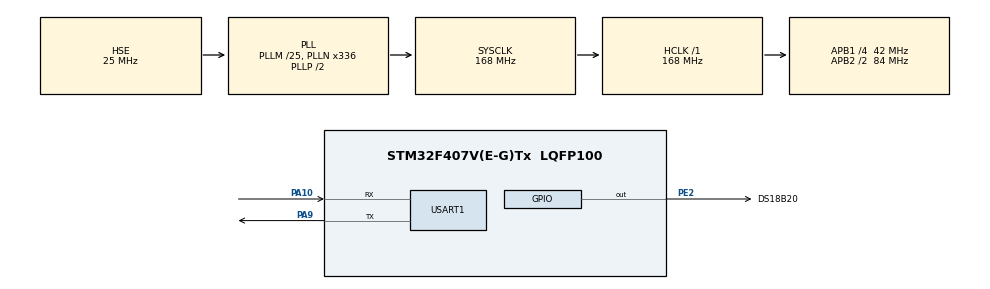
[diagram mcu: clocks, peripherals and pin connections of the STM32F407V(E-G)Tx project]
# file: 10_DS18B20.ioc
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Mcu.Family=STM32F4
Mcu.Name=STM32F407V(E-G)Tx
Mcu.Package=LQFP100
NVIC.PriorityGroup=NVIC_PRIORITYGROUP_4
PA10.GPIO_Speed=GPIO_SPEED_FREQ_HIGH
PA10.Mode=Asynchronous
PA10.Signal=USART1_RX
PA13.Mode=Serial_Wire
PA13.Signal=SYS_JTMS-SWDIO
PA14.Mode=Serial_Wire
PA14.Signal=SYS_JTCK-SWCLK
PA9.GPIO_Speed=GPIO_SPEED_FREQ_HIGH
PA9.Mode=Asynchronous
PA9.Signal=USART1_TX
PE2.GPIO_Label=DS18B20
PE2.Signal=GPIO_Output
PH0-OSC_IN.Mode=HSE-External-Oscillator
PH0-OSC_IN.Signal=RCC_OSC_IN
PH1-OSC_OUT.Mode=HSE-External-Oscillator
PH1-OSC_OUT.Signal=RCC_OSC_OUT
ProjectManager.HeapSize=0x200
ProjectManager.StackSize=0x400
ProjectManager.TargetToolchain=STM32CubeIDE
RCC.48MHZClocksFreq_Value=84000000
RCC.AHBFreq_Value=168000000
RCC.APB1CLKDivider=RCC_HCLK_DIV4
RCC.APB1Freq_Value=42000000
RCC.APB1TimFreq_Value=84000000
RCC.APB2CLKDivider=RCC_HCLK_DIV2
RCC.APB2Freq_Value=84000000
RCC.APB2TimFreq_Value=168000000
RCC.CortexFreq_Value=168000000
RCC.HCLKFreq_Value=168000000
RCC.HSE_VALUE=25000000
RCC.HSI_VALUE=16000000
RCC.LSE_VALUE=32768
RCC.PLLM=25
RCC.PLLN=336
RCC.PLLSourceVirtual=RCC_PLLSOURCE_HSE
RCC.SYSCLKFreq_VALUE=168000000
RCC.SYSCLKSource=RCC_SYSCLKSOURCE_PLLCLK
RCC.VCOOutputFreq_Value=336000000
TIM2.AutoReloadPreload=TIM_AUTORELOAD_PRELOAD_DISABLE
TIM2.Period=0xFFFFFFFF
TIM2.Prescaler=84-1
USART1.VirtualMode=VM_ASYNC
VP_TIM2_VS_ClockSourceINT.Mode=Internal
board=custom

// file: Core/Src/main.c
/* USER CODE BEGIN Header */
/**
  ******************************************************************************
  * @file           : main.c
  * @brief          : Main program body
  ******************************************************************************
  * @attention
  *
  * Copyright (c) 2025 STMicroelectronics.
  * All rights reserved.
  *
  * This software is licensed under terms that can be found in the LICENSE file
  * in the root directory of this software component.
  * If no LICENSE file comes with this software, it is provided AS-IS.
  *
  ******************************************************************************
  */
/* USER CODE END Header */
#include "main.h"
#include "tim.h"
#include "usart.h"
#include "gpio.h"

/* USER CODE BEGIN Includes */
#include <stdio.h>
/* USER CODE END Includes */

void SystemClock_Config(void);

/* USER CODE BEGIN 0 */
int _write(int file, char *ptr, int len)
{
  HAL_UART_Transmit(&huart1, (uint8_t *)ptr, len, 50);
  return len;
}

void delay_us(uint32_t us) {
    uint32_t start = __HAL_TIM_GET_COUNTER(&htim2);
    while((__HAL_TIM_GET_COUNTER(&htim2) - start) < us);
}

// Setting GPIO output mode
void DS18B20_GPIO_Output(void) {
    GPIO_InitTypeDef GPIO_InitStruct = {0};
    GPIO_InitStruct.Pin = DS18B20_Pin;
    GPIO_InitStruct.Mode = GPIO_MODE_OUTPUT_PP;
    GPIO_InitStruct.Speed = GPIO_SPEED_FREQ_LOW;
    HAL_GPIO_Init(DS18B20_GPIO_Port, &GPIO_InitStruct);
}

// Setting GPIO input mode (Pull-up)
void DS18B20_GPIO_Input(void) {
    GPIO_InitTypeDef GPIO_InitStruct = {0};
    GPIO_InitStruct.Pin = DS18B20_Pin;
    GPIO_InitStruct.Mode = GPIO_MODE_INPUT;
    GPIO_InitStruct.Pull = GPIO_PULLUP;
    HAL_GPIO_Init(DS18B20_GPIO_Port, &GPIO_InitStruct);
}

// **1-Wire Reset (Reset pulse & Presence detect)**
uint8_t DS18B20_Reset(void) {
    uint8_t presence = 0;

    DS18B20_GPIO_Output();
    HAL_GPIO_WritePin(DS18B20_GPIO_Port, DS18B20_Pin, GPIO_PIN_RESET);
    delay_us(480);

    DS18B20_GPIO_Input();
    delay_us(70);

    presence = HAL_GPIO_ReadPin(DS18B20_GPIO_Port, DS18B20_Pin);
    delay_us(410);

    return (presence == GPIO_PIN_RESET) ? 1 : 0;
}

// **1-Wire Write data (Write '1' or '0')**
void DS18B20_WriteBit(uint8_t bit) {
    DS18B20_GPIO_Output();
    HAL_GPIO_WritePin(DS18B20_GPIO_Port, DS18B20_Pin, GPIO_PIN_RESET);

    if (bit) {
        delay_us(1);
        DS18B20_GPIO_Input();
        delay_us(59);
    } else {
        delay_us(60);
        DS18B20_GPIO_Input();
    }
}

// **1-Wire Read data**
uint8_t DS18B20_ReadBit(void) {
    uint8_t bit = 0;

    DS18B20_GPIO_Output();
    HAL_GPIO_WritePin(DS18B20_GPIO_Port, DS18B20_Pin, GPIO_PIN_RESET);
    delay_us(1);

    DS18B20_GPIO_Input();
    delay_us(14);

    bit = HAL_GPIO_ReadPin(DS18B20_GPIO_Port, DS18B20_Pin);
    delay_us(45);

    return bit;
}

// **1-Wire Write bytes**
void DS18B20_WriteByte(uint8_t byte) {
    for (uint8_t i = 0; i < 8; i++) {
        DS18B20_WriteBit(byte & 0x01);
        byte >>= 1;
    }
}

// **1-Wire Read bytes**
uint8_t DS18B20_ReadByte(void) {
    uint8_t byte = 0;
    for (uint8_t i = 0; i < 8; i++) {
        if (DS18B20_ReadBit()) {
            byte |= (1 << i);
        }
    }
    return byte;
}

// **Temperature reading function**
float DS18B20_GetTemperature(void) {
    uint8_t temp_lsb, temp_msb;
    int16_t temp_raw;

    if (!DS18B20_Reset()) return -1000;

    DS18B20_WriteByte(0xCC);
    DS18B20_WriteByte(0x44);

    HAL_Delay(750);

    DS18B20_Reset();
    DS18B20_WriteByte(0xCC);
    DS18B20_WriteByte(0xBE);

    temp_lsb = DS18B20_ReadByte();
    temp_msb = DS18B20_ReadByte();

    temp_raw = (temp_msb << 8) | temp_lsb;

    return temp_raw / 16.0;
}
/* USER CODE END 0 */

int main(void)
{

  /* MCU Configuration--------------------------------------------------------*/

  /* Reset of all peripherals, Initializes the Flash interface and the Systick. */
  HAL_Init();

  /* Configure the system clock */
  SystemClock_Config();

  /* Initialize all configured peripherals */
  MX_GPIO_Init();
  MX_USART1_UART_Init();
  MX_TIM2_Init();
  /* USER CODE BEGIN 2 */
  HAL_TIM_Base_Start(&htim2);
  /* USER CODE END 2 */

  /* Infinite loop */
  while (1)
  {

    /* USER CODE BEGIN 3 */
    float temperature = DS18B20_GetTemperature();
    if (temperature != -1000) {
        printf("Temperature: %.2f°C\n", temperature);
    } else {
        printf("DS18B20 not detected!\n");
    }
    HAL_Delay(1000);

  }
  /* USER CODE END 3 */
}

void SystemClock_Config(void)
{
  RCC_OscInitTypeDef RCC_OscInitStruct = {0};
  RCC_ClkInitTypeDef RCC_ClkInitStruct = {0};

  /** Configure the main internal regulator output voltage
  */
  __HAL_RCC_PWR_CLK_ENABLE();
  __HAL_PWR_VOLTAGESCALING_CONFIG(PWR_REGULATOR_VOLTAGE_SCALE1);

  /** Initializes the RCC Oscillators according to the specified parameters
  * in the RCC_OscInitTypeDef structure.
  */
  RCC_OscInitStruct.OscillatorType = RCC_OSCILLATORTYPE_HSE;
  RCC_OscInitStruct.HSEState = RCC_HSE_ON;
  RCC_OscInitStruct.PLL.PLLState = RCC_PLL_ON;
  RCC_OscInitStruct.PLL.PLLSource = RCC_PLLSOURCE_HSE;
  RCC_OscInitStruct.PLL.PLLM = 25;
  RCC_OscInitStruct.PLL.PLLN = 336;
  RCC_OscInitStruct.PLL.PLLP = RCC_PLLP_DIV2;
  RCC_OscInitStruct.PLL.PLLQ = 4;
  if (HAL_RCC_OscConfig(&RCC_OscInitStruct) != HAL_OK)
  {
    Error_Handler();
  }

  /** Initializes the CPU, AHB and APB buses clocks
  */
  RCC_ClkInitStruct.ClockType = RCC_CLOCKTYPE_HCLK|RCC_CLOCKTYPE_SYSCLK
                              |RCC_CLOCKTYPE_PCLK1|RCC_CLOCKTYPE_PCLK2;
  RCC_ClkInitStruct.SYSCLKSource = RCC_SYSCLKSOURCE_PLLCLK;
  RCC_ClkInitStruct.AHBCLKDivider = RCC_SYSCLK_DIV1;
  RCC_ClkInitStruct.APB1CLKDivider = RCC_HCLK_DIV4;
  RCC_ClkInitStruct.APB2CLKDivider = RCC_HCLK_DIV2;

  if (HAL_RCC_ClockConfig(&RCC_ClkInitStruct, FLASH_LATENCY_5) != HAL_OK)
  {
    Error_Handler();
  }
}

void Error_Handler(void)
{
  __disable_irq();
  while (1)
  {
  }
}
